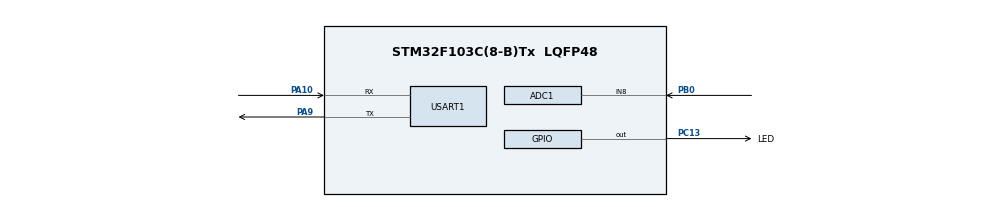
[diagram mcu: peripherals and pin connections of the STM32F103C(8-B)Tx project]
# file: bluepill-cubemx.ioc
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ADC1.Channel-1\#ChannelRegularConversion=ADC_CHANNEL_8
ADC1.NbrOfConversionFlag=1
ADC1.Rank-1\#ChannelRegularConversion=1
ADC1.SamplingTime-1\#ChannelRegularConversion=ADC_SAMPLETIME_1CYCLE_5
ADC1.master=1
Mcu.Family=STM32F1
Mcu.Name=STM32F103C(8-B)Tx
Mcu.Package=LQFP48
NVIC.ADC1_2_IRQn=true\:0\:0\:false\:false\:true\:true\:true\:true
NVIC.PriorityGroup=NVIC_PRIORITYGROUP_4
PA10.Mode=Asynchronous
PA10.Signal=USART1_RX
PA13.Mode=Serial_Wire
PA13.Signal=SYS_JTMS-SWDIO
PA14.Mode=Serial_Wire
PA14.Signal=SYS_JTCK-SWCLK
PA9.Mode=Asynchronous
PA9.Signal=USART1_TX
PB0.Signal=ADCx_IN8
PC13-TAMPER-RTC.GPIO_Label=LED
PC13-TAMPER-RTC.PinState=GPIO_PIN_SET
PC13-TAMPER-RTC.Signal=GPIO_Output
PD0-OSC_IN.Mode=HSE-External-Oscillator
PD0-OSC_IN.Signal=RCC_OSC_IN
PD1-OSC_OUT.Mode=HSE-External-Oscillator
PD1-OSC_OUT.Signal=RCC_OSC_OUT
ProjectManager.HeapSize=0x200
ProjectManager.StackSize=0x400
ProjectManager.TargetToolchain=STM32CubeIDE
RCC.ADCPresc=RCC_ADCPCLK2_DIV6
RCC.AHBFreq_Value=64000000
RCC.APB1CLKDivider=RCC_HCLK_DIV2
RCC.APB1Freq_Value=32000000
RCC.APB1TimFreq_Value=64000000
RCC.APB2Freq_Value=64000000
RCC.APB2TimFreq_Value=64000000
RCC.HCLKFreq_Value=64000000
RCC.PLLMUL=RCC_PLL_MUL8
RCC.PLLSourceVirtual=RCC_PLLSOURCE_HSE
RCC.SYSCLKFreq_VALUE=64000000
RCC.SYSCLKSource=RCC_SYSCLKSOURCE_PLLCLK
RCC.USBFreq_Value=64000000
SH.ADCx_IN8.0=ADC1_IN8,IN8
USART1.VirtualMode=VM_ASYNC
board=custom

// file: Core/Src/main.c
/* USER CODE BEGIN Header */
/**
  ******************************************************************************
  * @file           : main.c
  * @brief          : Main program body
  ******************************************************************************
  * @attention
  *
  * Copyright (c) 2022 STMicroelectronics.
  * All rights reserved.
  *
  * This software is licensed under terms that can be found in the LICENSE file
  * in the root directory of this software component.
  * If no LICENSE file comes with this software, it is provided AS-IS.
  *
  ******************************************************************************
  */
/* USER CODE END Header */
#include "main.h"
#include "adc.h"
#include "usart.h"
#include "gpio.h"

/* USER CODE BEGIN Includes */
#include <stdio.h>

/* USER CODE END Includes */

void SystemClock_Config(void);

int main(void)
{

  /* MCU Configuration--------------------------------------------------------*/

  /* Reset of all peripherals, Initializes the Flash interface and the Systick. */
  HAL_Init();

  /* Configure the system clock */
  SystemClock_Config();

  /* Initialize all configured peripherals */
  MX_GPIO_Init();
  MX_USART1_UART_Init();
  MX_ADC1_Init();
  /* USER CODE BEGIN 2 */
    printf("test\r\n");
    ADC1->CR2 |= ADC_CR2_ADON;
    ADC1->CR1 |= ADC_CR1_EOCIE;
    while (!(ADC1->CR2 & ADC_CR2_ADON));
    ADC1->CR2 |= ADC_CR2_SWSTART | ADC_CR2_EXTTRIG;
    printf("swstart\r\n");

  /* USER CODE END 2 */

  /* Infinite loop */
  while (1)
  {

  }
}

void SystemClock_Config(void)
{
  LL_FLASH_SetLatency(LL_FLASH_LATENCY_2);
  while(LL_FLASH_GetLatency()!= LL_FLASH_LATENCY_2)
  {
  }
  LL_RCC_HSE_Enable();

   /* Wait till HSE is ready */
  while(LL_RCC_HSE_IsReady() != 1)
  {

  }
  LL_RCC_PLL_ConfigDomain_SYS(LL_RCC_PLLSOURCE_HSE_DIV_1, LL_RCC_PLL_MUL_8);
  LL_RCC_PLL_Enable();

   /* Wait till PLL is ready */
  while(LL_RCC_PLL_IsReady() != 1)
  {

  }
  LL_RCC_SetAHBPrescaler(LL_RCC_SYSCLK_DIV_1);
  LL_RCC_SetAPB1Prescaler(LL_RCC_APB1_DIV_2);
  LL_RCC_SetAPB2Prescaler(LL_RCC_APB2_DIV_1);
  LL_RCC_SetSysClkSource(LL_RCC_SYS_CLKSOURCE_PLL);

   /* Wait till System clock is ready */
  while(LL_RCC_GetSysClkSource() != LL_RCC_SYS_CLKSOURCE_STATUS_PLL)
  {

  }
  LL_SetSystemCoreClock(64000000);

   /* Update the time base */
  if (HAL_InitTick (TICK_INT_PRIORITY) != HAL_OK)
  {
    Error_Handler();
  }
  LL_RCC_SetADCClockSource(LL_RCC_ADC_CLKSRC_PCLK2_DIV_6);
}

void Error_Handler(void)
{
  __disable_irq();
  while (1)
  {
  }
}
